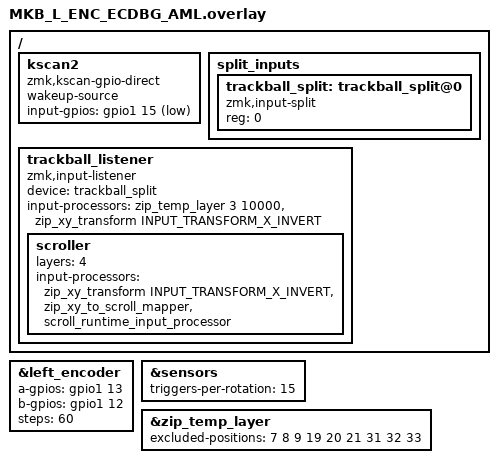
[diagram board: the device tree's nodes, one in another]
#include <input/processors.dtsi>
#include <dt-bindings/zmk/input_transform.h>

/* ECDBG encoder module */
&left_encoder {
    status = "okay";
    a-gpios = <&gpio1 13 GPIO_ACTIVE_HIGH>;
    b-gpios = <&gpio1 12 GPIO_ACTIVE_HIGH>;
    steps = <60>;
};

&sensors {
    triggers-per-rotation = <15>;
};

/delete-node/ &kscan2;

/ {
    kscan2: kscan2 {
        compatible = "zmk,kscan-gpio-direct";
        wakeup-source;
        input-gpios = <&gpio1 15 (GPIO_ACTIVE_LOW | GPIO_PULL_UP)>;
    };
};

/* Right-side trackball input received on central side */
 / {
    split_inputs {
        #address-cells = <1>;
        #size-cells = <0>;

        trackball_split: trackball_split@0 {
            compatible = "zmk,input-split";
            reg = <0>;
        };
    };

    trackball_listener: trackball_listener {
        compatible = "zmk,input-listener";
        status = "okay";
        device = <&trackball_split>;

        /*
         * Trackball movement:
         * - enter Mouse layer 3 for 10 seconds
         * - normal movement stays as mouse movement
         */
        input-processors =
            <&zip_temp_layer 3 10000>,
            <&zip_xy_transform INPUT_TRANSFORM_X_INVERT>;

        /*
         * Scroll layer 4:
         * when layer 4 is active, trackball becomes scroll
         */
        scroller {
            layers = <4>;
            input-processors =
                <&zip_xy_transform INPUT_TRANSFORM_X_INVERT>,
                <&zip_xy_to_scroll_mapper &scroll_runtime_input_processor>;
        };
    };
};

&zip_temp_layer {
    excluded-positions = <
        7  8  9
        19 20 21
        31 32 33
    >;
};
